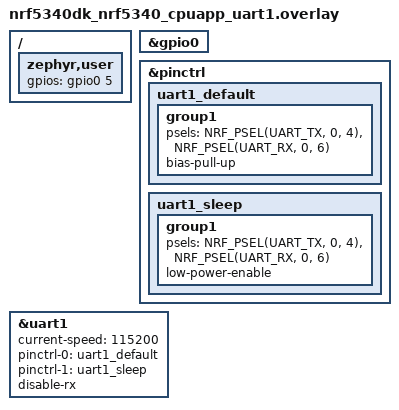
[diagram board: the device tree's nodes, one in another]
/*
 * Test requires wire connection between:
 *  - uart1 TX at P0.04 <-> GPIO input at P0.05
 */

/ {
	zephyr,user {
		gpios = <&gpio0 5 GPIO_ACTIVE_HIGH>;
	};
};

&gpio0 {
	status = "okay";
};

&pinctrl {
	uart1_default: uart1_default {
		group1 {
			psels = <NRF_PSEL(UART_TX, 0, 4)>,
				<NRF_PSEL(UART_RX, 0, 6)>;
			bias-pull-up;
		};
	};

	uart1_sleep: uart1_sleep {
		group1 {
			psels = <NRF_PSEL(UART_TX, 0, 4)>,
				<NRF_PSEL(UART_RX, 0, 6)>;
			low-power-enable;
		};
	};
};

dut: &uart1 {
	status = "okay";
	current-speed = <115200>;
	pinctrl-0 = <&uart1_default>;
	pinctrl-1 = <&uart1_sleep>;
	pinctrl-names = "default", "sleep";
	disable-rx;
};
